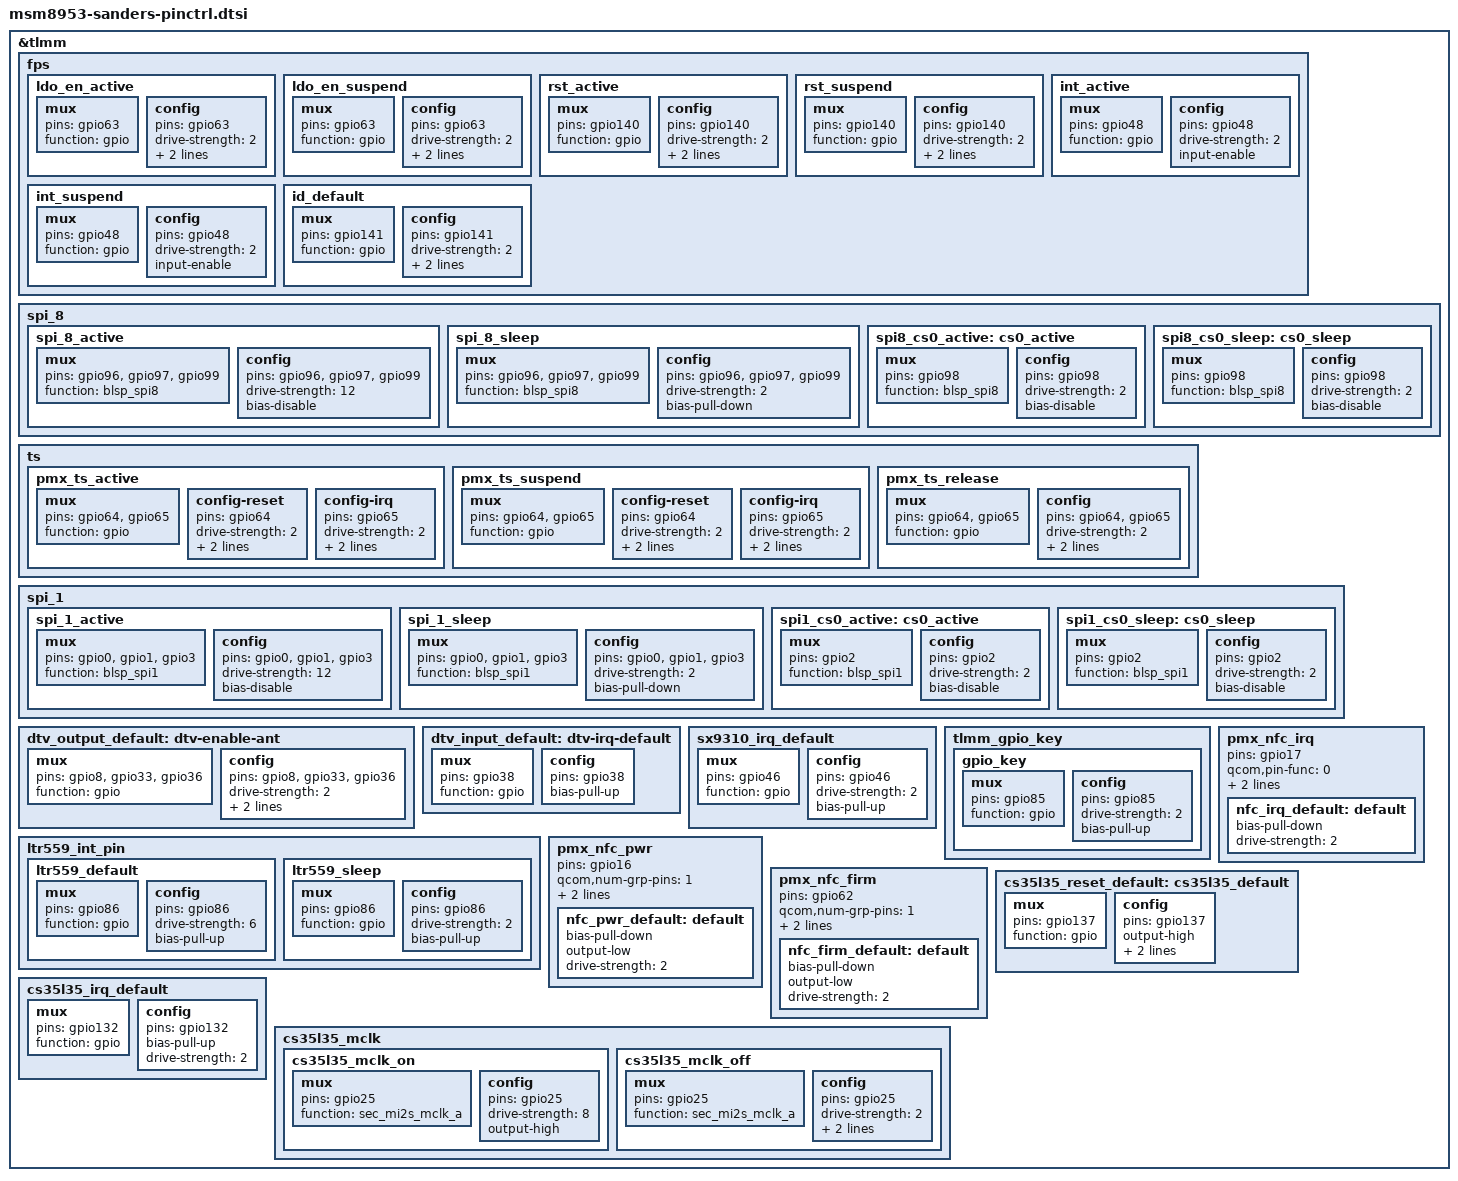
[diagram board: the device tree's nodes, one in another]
/* adapted from MotorolaMobilityLLC/kernel-msm oreo-8.1.0-release-sanders
 * msm8953-sanders-pinctrl.dtsi (fps/spi states) plus touch states for
 * the imren focaltech_touch driver (pmx_ts_*). gpios from stock dt.
 */

&tlmm {
	fps: fps {
		ldo_en_active: ldo_en_active {
			/* LDO ENABLE */
			mux {
				pins = "gpio63";
				function = "gpio";
			};

			config {
				pins = "gpio63";
				drive-strength = <2>; /* 2 MA */
				bias-pull-up; /* pull up */
				output-high;
			};
		};

		ldo_en_suspend: ldo_en_suspend {
			/* LDO ENABLE */
			mux {
				pins = "gpio63";
				function = "gpio";
			};

			config {
				pins = "gpio63";
				drive-strength = <2>; /* 2 MA */
				bias-pull-up; /* pull up */
				output-high;
			};
		};

		rst_active: rst_active {
			/* RESET */
			mux {
				pins = "gpio140";
				function = "gpio";
			};

			config {
				pins = "gpio140";
				drive-strength = <2>; /* 2 MA */
				bias-pull-up; /* pull up */
				output-high;
			};
		};

		rst_suspend: rst_suspend {
			/* RESET */
			mux {
				pins = "gpio140";
				function = "gpio";
			};

			config {
				pins = "gpio140";
				drive-strength = <2>; /* 2 MA */
				bias-pull-up; /* pull up */
				output-high;
			};
		};

		int_active: int_active {
			/* INTERRUPT */
			mux {
				pins = "gpio48";
				function = "gpio";
			};

			config {
				pins = "gpio48";
				drive-strength = <2>; /* 2 MA */
				input-enable;
			};
		};

		int_suspend: int_suspend {
			/* INTERRUPT */
			mux {
				pins = "gpio48";
				function = "gpio";
			};

			config {
				pins = "gpio48";
				drive-strength = <2>; /* 2 MA */
				input-enable;
			};
		};

		id_default: id_default {
			/* ID */
			mux {
				pins = "gpio141";
				function = "gpio";
			};

			config {
				pins = "gpio141";
				drive-strength = <2>; /* 2 MA */
				bias-disable;
				input-enable;
			};
		};
	};

	spi_8 {
		spi_8_active: spi_8_active {
			mux {
				/* MOSI, MISO, CLK */
				pins = "gpio96", "gpio97", "gpio99";
				function = "blsp_spi8";
			};

			config {
				pins = "gpio96", "gpio97", "gpio99";
				drive-strength = <12>; /* 12 MA */
				bias-disable; /* No PULL */
			};
		};

		spi_8_sleep: spi_8_sleep {
			mux {
				/* MOSI, MISO, CLK */
				pins = "gpio96", "gpio97", "gpio99";
				function = "blsp_spi8";
			};

			config {
				pins = "gpio96", "gpio97", "gpio99";
				drive-strength = <2>; /* 2 MA */
				bias-pull-down; /* PULL Down */
			};
		};

		spi8_cs0_active: cs0_active {
			mux {
				pins = "gpio98";
				function = "blsp_spi8";
			};

			config {
				pins = "gpio98";
				drive-strength = <2>;
				bias-disable;
			};
		};

		spi8_cs0_sleep: cs0_sleep {
			mux {
				pins = "gpio98";
				function = "blsp_spi8";
			};

			config {
				pins = "gpio98";
				drive-strength = <2>;
				bias-disable;
			};
		};
	};

	ts: ts {
		/* FT5436 reset gpio64 + irq gpio65, state names required
		 * by the focaltech_touch driver.
		 */
		pmx_ts_active: pmx_ts_active {
			mux {
				pins = "gpio64", "gpio65";
				function = "gpio";
			};

			config-reset {
				pins = "gpio64";
				drive-strength = <2>;
				bias-pull-up;
				output-high;
			};

			config-irq {
				pins = "gpio65";
				drive-strength = <2>;
				bias-pull-up;
				input-enable;
			};
		};

		pmx_ts_suspend: pmx_ts_suspend {
			mux {
				pins = "gpio64", "gpio65";
				function = "gpio";
			};

			config-reset {
				pins = "gpio64";
				drive-strength = <2>;
				bias-pull-down;
				output-low;
			};

			config-irq {
				pins = "gpio65";
				drive-strength = <2>;
				bias-pull-down;
				input-enable;
			};
		};

		pmx_ts_release: pmx_ts_release {
			mux {
				pins = "gpio64", "gpio65";
				function = "gpio";
			};

			config {
				pins = "gpio64", "gpio65";
				drive-strength = <2>;
				bias-pull-down;
				input-enable;
			};
		};
	};

	spi_1 {
		spi_1_active: spi_1_active {
			mux {
				pins = "gpio0", "gpio1", "gpio3";
				function = "blsp_spi1";
			};

			config {
				pins = "gpio0", "gpio1", "gpio3";
				drive-strength = <12>;
				bias-disable;
			};
		};

		spi_1_sleep: spi_1_sleep {
			mux {
				pins = "gpio0", "gpio1", "gpio3";
				function = "blsp_spi1";
			};

			config {
				pins = "gpio0", "gpio1", "gpio3";
				drive-strength = <2>;
				bias-pull-down;
			};
		};

		spi1_cs0_active: cs0_active {
			mux {
				pins = "gpio2";
				function = "blsp_spi1";
			};

			config {
				pins = "gpio2";
				drive-strength = <2>;
				bias-disable;
			};
		};

		spi1_cs0_sleep: cs0_sleep {
			mux {
				pins = "gpio2";
				function = "blsp_spi1";
			};

			config {
				pins = "gpio2";
				drive-strength = <2>;
				bias-disable;
			};
		};
	};

	dtv_output_default: dtv-enable-ant {
		mux {
			pins = "gpio8", "gpio33","gpio36";
			function = "gpio";
		};
		config {
			pins = "gpio8", "gpio33","gpio36";
			drive-strength = <2>;
			bias-disable;
			output-low;
		};
	};

	dtv_input_default: dtv-irq-default {
		mux {
			pins = "gpio38";
			function = "gpio";
		};
		config {
			pins = "gpio38";
			bias-pull-up;
		};
	};

	sx9310_irq_default: sx9310_irq_default {
		mux {
			pins = "gpio46";
			function = "gpio";
		};

		config {
			pins = "gpio46";
			drive-strength = <2>;
			bias-pull-up;
		};
	};

	ltr559_int_pin {
		ltr559_default: ltr559_default {
			mux {
				pins = "gpio86";
				function = "gpio";
			};
			config {
				pins = "gpio86";
				drive-strength = <6>;
				bias-pull-up;
			};
		};
		ltr559_sleep: ltr559_sleep {
			mux {
				pins = "gpio86";
				function = "gpio";
			};
			config {
				pins = "gpio86";
				drive-strength = <2>;
				bias-pull-up;
			};
		};
	};

	tlmm_gpio_key {
		gpio_key: gpio_key {
			mux {
				pins = "gpio85";
				function = "gpio";
			};
			config {
				pins = "gpio85";
				drive-strength = <2>;
				bias-pull-up;
			};
		};
	};

	pmx_nfc_irq {
		pins = "gpio17";
		qcom,pin-func = <0>;
		qcom,num-grp-pins = <1>;
		label = "nfc_irq";

		nfc_irq_default: default {
			bias-pull-down;
			drive-strength = <2>;
		};
	};

	pmx_nfc_pwr {
		pins = "gpio16";
		qcom,num-grp-pins = <1>;
		qcom,pin-func = <0>;
		label = "nfc_pwr";

		nfc_pwr_default: default {
			bias-pull-down;
			output-low;
			drive-strength = <2>;
		};
	};

	pmx_nfc_firm {
		pins = "gpio62";
		qcom,num-grp-pins = <1>;
		qcom,pin-func = <0>;
		label = "nfc_firm";

		nfc_firm_default: default {
			bias-pull-down;
			output-low;
			drive-strength = <2>;
		};
	};

	cs35l35_reset_default: cs35l35_default{
		mux {
			pins = "gpio137";
			function = "gpio";
		};

		config {
			pins = "gpio137";
			output-high;
			bias-pull-up;
			drive-strength = <2>;
		};
	};

	cs35l35_irq_default: cs35l35_irq_default {
		mux {
			pins = "gpio132";
			function = "gpio";
		};

		config {
			pins = "gpio132";
			bias-pull-up;
			drive-strength = <2>;
		};
	};

	cs35l35_mclk {
		cs35l35_mclk_on: cs35l35_mclk_on {
			mux {
				pins = "gpio25";
				function = "sec_mi2s_mclk_a";
			};

			config {
				pins = "gpio25";
				drive-strength = <8>; /* 8 MA */
				output-high;
			};
		};

		cs35l35_mclk_off: cs35l35_mclk_off {
			mux {
				pins = "gpio25";
				function = "sec_mi2s_mclk_a";
			};

			config {
				pins = "gpio25";
				drive-strength = <2>; /* 2 MA */
				output-low;
				bias-pull-down;
			};
		};
	};
};
